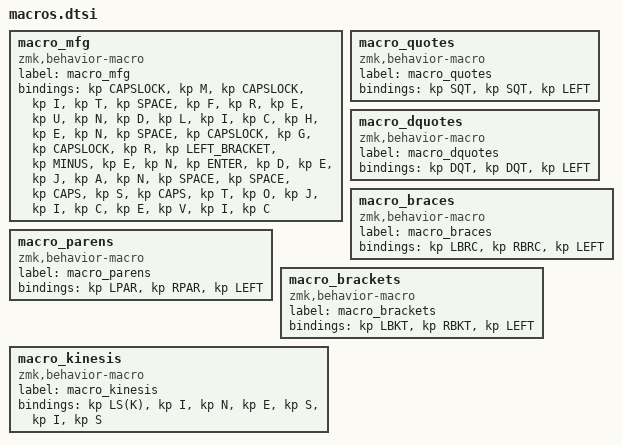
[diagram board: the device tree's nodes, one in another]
macro_mfg: macro_mfg{
compatible = "zmk,behavior-macro";
label = "macro_mfg";
#binding-cells = <0>;
bindings = <&kp CAPSLOCK>, <&kp M>, <&kp CAPSLOCK>, <&kp I>, <&kp T>, <&kp SPACE>, <&kp F>, <&kp R>, <&kp E>, <&kp U>, <&kp N>, <&kp D>, <&kp L>, <&kp I>, <&kp C>, <&kp H>, <&kp E>, <&kp N>, <&kp SPACE>, <&kp CAPSLOCK>, <&kp G>, <&kp CAPSLOCK>, <&kp R>, <&kp LEFT_BRACKET>, <&kp MINUS>, <&kp E>, <&kp N>, <&kp ENTER>, <&kp D>, <&kp E>, <&kp J>, <&kp A>, <&kp N>, <&kp SPACE>, <&kp SPACE>, <&kp CAPS>, <&kp S>, <&kp CAPS>, <&kp T>, <&kp O>, <&kp J>, <&kp I>, <&kp C>, <&kp E>, <&kp V>, <&kp I>, <&kp C>;
};
macro_quotes: macro_quotes{
compatible = "zmk,behavior-macro";
label = "macro_quotes";
#binding-cells = <0>;
bindings = <&kp SQT>, <&kp SQT>, <&kp LEFT>;
};
macro_dquotes: macro_dquotes{
compatible = "zmk,behavior-macro";
label = "macro_dquotes";
#binding-cells = <0>;
bindings = <&kp DQT>, <&kp DQT>, <&kp LEFT>;
};
macro_braces: macro_braces{
compatible = "zmk,behavior-macro";
label = "macro_braces";
#binding-cells = <0>;
bindings = <&kp LBRC>, <&kp RBRC>, <&kp LEFT>;
};
macro_parens: macro_parens{
compatible = "zmk,behavior-macro";
label = "macro_parens";
#binding-cells = <0>;
bindings = <&kp LPAR>, <&kp RPAR>, <&kp LEFT>;
};
macro_brackets: macro_brackets{
compatible = "zmk,behavior-macro";
label = "macro_brackets";
#binding-cells = <0>;
bindings = <&kp LBKT>, <&kp RBKT>, <&kp LEFT>;
};
macro_kinesis: macro_kinesis{
compatible = "zmk,behavior-macro";
label = "macro_kinesis";
#binding-cells = <0>;
bindings = <&kp LS(K)>, <&kp I>, <&kp N>, <&kp E>, <&kp S>, <&kp I>, <&kp S>;
};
